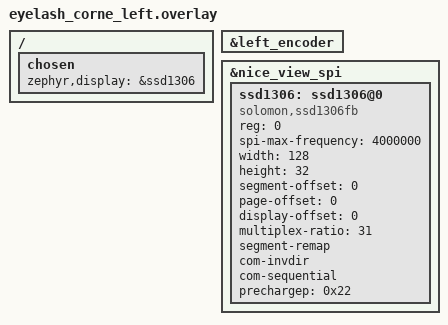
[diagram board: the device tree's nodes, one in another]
/*
*
* Copyright (c) 2024 The ZMK Contributors
* SPDX-License-Identifier: MIT
*
*/

#include "eyelash_corne.dtsi"
#include <behaviors/battery_history_request.dtsi>
#include <input/processors.dtsi>
#include <input/processors/runtime-input-processor.dtsi>

&left_encoder {
    status = "okay";
};

&nice_view_spi {
    status = "okay";
    ssd1306: ssd1306@0 {
        compatible = "solomon,ssd1306fb";
        reg = <0>;
        spi-max-frequency = <4000000>;
        width = <128>;
        height = <32>;
        segment-offset = <0>;
        page-offset = <0>;
        display-offset = <0>;
        multiplex-ratio = <31>;
        segment-remap;
        com-invdir;
        com-sequential;
        prechargep = <0x22>;
    };
};

/ {
    chosen {
        zephyr,display = &ssd1306;
    };
};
